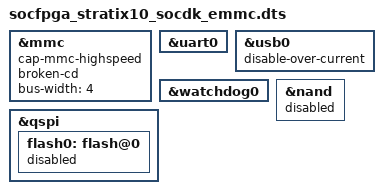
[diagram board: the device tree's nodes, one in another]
// SPDX-License-Identifier: GPL-2.0-only
/*
 * Copyright Altera Corporation (C) 2026. All rights reserved.
 */

#include "socfpga_stratix10_socdk_nand.dts"

&mmc {
	status = "okay";
	cap-mmc-highspeed;
	broken-cd;
	bus-width = <4>;
	bootph-all;
};

&uart0 {
	status = "okay";
};

&usb0 {
	status = "okay";
	disable-over-current;
};

&watchdog0 {
	status = "okay";
};

&nand {
	status = "disabled";
};

&qspi {
	flash0: flash@0 {
		status = "disabled";
	};
};
